# ESP32-C6 register map
Vendor: ESPRESSIF SYSTEMS (SHANGHAI) CO., LTD.; Series: ESP32 C-Series; File version: 12
CPU: RV32IMAC r0p0, little endian, no MPU, no FPU, 0 interrupt priority bits
Address unit: 32 bits
Registers are 32-bit, read-write, reset 0x0 unless marked. A register's access mark holds for its fields unless they carry their own. Offsets are from the block's base; [hi:lo] are bit positions.

## ASSIST_DEBUG — Debug Assist
Base 0x600C2000
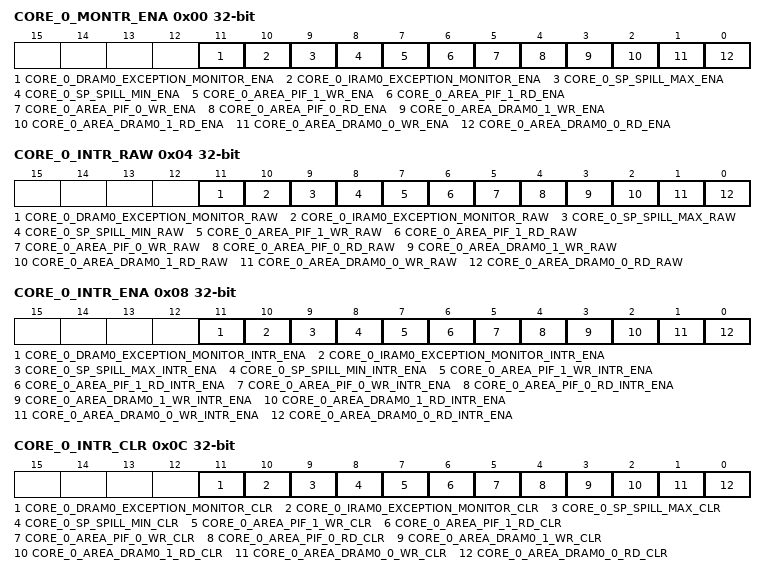
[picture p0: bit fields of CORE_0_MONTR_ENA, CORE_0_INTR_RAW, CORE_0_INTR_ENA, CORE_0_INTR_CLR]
0x00 CORE_0_MONTR_ENA — core0 monitor enable configuration register
  [11] CORE_0_DRAM0_EXCEPTION_MONITOR_ENA — DBUS busy monitor enbale
  [10] CORE_0_IRAM0_EXCEPTION_MONITOR_ENA — IBUS busy monitor enable
  [9] CORE_0_SP_SPILL_MAX_ENA — Core0 stackpoint overflow monitor enable
  [8] CORE_0_SP_SPILL_MIN_ENA — Core0 stackpoint underflow monitor enable
  [7] CORE_0_AREA_PIF_1_WR_ENA — Core0 PIF area1 write monitor enable
  [6] CORE_0_AREA_PIF_1_RD_ENA — Core0 PIF area1 read monitor enable
  [5] CORE_0_AREA_PIF_0_WR_ENA — Core0 PIF area0 write monitor enable
  [4] CORE_0_AREA_PIF_0_RD_ENA — Core0 PIF area0 read monitor enable
  [3] CORE_0_AREA_DRAM0_1_WR_ENA — Core0 dram0 area1 write monitor enable
  [2] CORE_0_AREA_DRAM0_1_RD_ENA — Core0 dram0 area1 read monitor enable
  [1] CORE_0_AREA_DRAM0_0_WR_ENA — Core0 dram0 area0 write monitor enable
  [0] CORE_0_AREA_DRAM0_0_RD_ENA — Core0 dram0 area0 read monitor enable
0x04 CORE_0_INTR_RAW ro — core0 monitor interrupt status register
  [11] CORE_0_DRAM0_EXCEPTION_MONITOR_RAW — DBUS busy monitor initerrupt status
  [10] CORE_0_IRAM0_EXCEPTION_MONITOR_RAW — IBUS busy monitor interrupt status
  [9] CORE_0_SP_SPILL_MAX_RAW — Core0 stackpoint overflow monitor interrupt status
  [8] CORE_0_SP_SPILL_MIN_RAW — Core0 stackpoint underflow monitor interrupt status
  [7] CORE_0_AREA_PIF_1_WR_RAW — Core0 PIF area1 write monitor interrupt status
  [6] CORE_0_AREA_PIF_1_RD_RAW — Core0 PIF area1 read monitor interrupt status
  [5] CORE_0_AREA_PIF_0_WR_RAW — Core0 PIF area0 write monitor interrupt status
  [4] CORE_0_AREA_PIF_0_RD_RAW — Core0 PIF area0 read monitor interrupt status
  [3] CORE_0_AREA_DRAM0_1_WR_RAW — Core0 dram0 area1 write monitor interrupt status
  [2] CORE_0_AREA_DRAM0_1_RD_RAW — Core0 dram0 area1 read monitor interrupt status
  [1] CORE_0_AREA_DRAM0_0_WR_RAW — Core0 dram0 area0 write monitor interrupt status
  [0] CORE_0_AREA_DRAM0_0_RD_RAW — Core0 dram0 area0 read monitor interrupt status
0x08 CORE_0_INTR_ENA — core0 monitor interrupt enable register
  [11] CORE_0_DRAM0_EXCEPTION_MONITOR_INTR_ENA — DBUS busy monitor interrupt enbale
  [10] CORE_0_IRAM0_EXCEPTION_MONITOR_INTR_ENA — IBUS busy monitor interrupt enable
  [9] CORE_0_SP_SPILL_MAX_INTR_ENA — Core0 stackpoint overflow monitor interrupt enable
  [8] CORE_0_SP_SPILL_MIN_INTR_ENA — Core0 stackpoint underflow monitor interrupt enable
  [7] CORE_0_AREA_PIF_1_WR_INTR_ENA — Core0 PIF area1 write monitor interrupt enable
  [6] CORE_0_AREA_PIF_1_RD_INTR_ENA — Core0 PIF area1 read monitor interrupt enable
  [5] CORE_0_AREA_PIF_0_WR_INTR_ENA — Core0 PIF area0 write monitor interrupt enable
  [4] CORE_0_AREA_PIF_0_RD_INTR_ENA — Core0 PIF area0 read monitor interrupt enable
  [3] CORE_0_AREA_DRAM0_1_WR_INTR_ENA — Core0 dram0 area1 write monitor interrupt enable
  [2] CORE_0_AREA_DRAM0_1_RD_INTR_ENA — Core0 dram0 area1 read monitor interrupt enable
  [1] CORE_0_AREA_DRAM0_0_WR_INTR_ENA — Core0 dram0 area0 write monitor interrupt enable
  [0] CORE_0_AREA_DRAM0_0_RD_INTR_ENA — Core0 dram0 area0 read monitor interrupt enable
0x0C CORE_0_INTR_CLR wo — core0 monitor interrupt clr register
  [11] CORE_0_DRAM0_EXCEPTION_MONITOR_CLR — DBUS busy monitor interrupt clr
  [10] CORE_0_IRAM0_EXCEPTION_MONITOR_CLR — IBUS busy monitor interrupt clr
  [9] CORE_0_SP_SPILL_MAX_CLR — Core0 stackpoint overflow monitor interrupt clr
  [8] CORE_0_SP_SPILL_MIN_CLR — Core0 stackpoint underflow monitor interrupt clr
  [7] CORE_0_AREA_PIF_1_WR_CLR — Core0 PIF area1 write monitor interrupt clr
  [6] CORE_0_AREA_PIF_1_RD_CLR — Core0 PIF area1 read monitor interrupt clr
  [5] CORE_0_AREA_PIF_0_WR_CLR — Core0 PIF area0 write monitor interrupt clr
  [4] CORE_0_AREA_PIF_0_RD_CLR — Core0 PIF area0 read monitor interrupt clr
  [3] CORE_0_AREA_DRAM0_1_WR_CLR — Core0 dram0 area1 write monitor interrupt clr
  [2] CORE_0_AREA_DRAM0_1_RD_CLR — Core0 dram0 area1 read monitor interrupt clr
  [1] CORE_0_AREA_DRAM0_0_WR_CLR — Core0 dram0 area0 write monitor interrupt clr
  [0] CORE_0_AREA_DRAM0_0_RD_CLR — Core0 dram0 area0 read monitor interrupt clr
0x10 CORE_0_AREA_DRAM0_0_MIN reset 0xFFFFFFFF — core0 dram0 region0 addr configuration register
  [31:0] CORE_0_AREA_DRAM0_0_MIN — Core0 dram0 region0 start addr
0x14 CORE_0_AREA_DRAM0_0_MAX — core0 dram0 region0 addr configuration register
  [31:0] CORE_0_AREA_DRAM0_0_MAX — Core0 dram0 region0 end addr
0x18 CORE_0_AREA_DRAM0_1_MIN reset 0xFFFFFFFF — core0 dram0 region1 addr configuration register
  [31:0] CORE_0_AREA_DRAM0_1_MIN — Core0 dram0 region1 start addr
0x1C CORE_0_AREA_DRAM0_1_MAX — core0 dram0 region1 addr configuration register
  [31:0] CORE_0_AREA_DRAM0_1_MAX — Core0 dram0 region1 end addr
0x20 CORE_0_AREA_PIF_0_MIN reset 0xFFFFFFFF — core0 PIF region0 addr configuration register
  [31:0] CORE_0_AREA_PIF_0_MIN — Core0 PIF region0 start addr
0x24 CORE_0_AREA_PIF_0_MAX — core0 PIF region0 addr configuration register
  [31:0] CORE_0_AREA_PIF_0_MAX — Core0 PIF region0 end addr
0x28 CORE_0_AREA_PIF_1_MIN reset 0xFFFFFFFF — core0 PIF region1 addr configuration register
  [31:0] CORE_0_AREA_PIF_1_MIN — Core0 PIF region1 start addr
0x2C CORE_0_AREA_PIF_1_MAX — core0 PIF region1 addr configuration register
  [31:0] CORE_0_AREA_PIF_1_MAX — Core0 PIF region1 end addr
0x30 CORE_0_AREA_PC ro — core0 area pc status register
  [31:0] CORE_0_AREA_PC — the stackpointer when first touch region monitor interrupt
0x34 CORE_0_AREA_SP ro — core0 area sp status register
  [31:0] CORE_0_AREA_SP — the PC when first touch region monitor interrupt
0x38 CORE_0_SP_MIN — stack min value
  [31:0] CORE_0_SP_MIN — core0 sp region configuration regsiter
0x3C CORE_0_SP_MAX reset 0xFFFFFFFF — stack max value
  [31:0] CORE_0_SP_MAX — core0 sp pc status register
0x40 CORE_0_SP_PC ro — stack monitor pc status register
  [31:0] CORE_0_SP_PC — This regsiter stores the PC when trigger stack monitor.
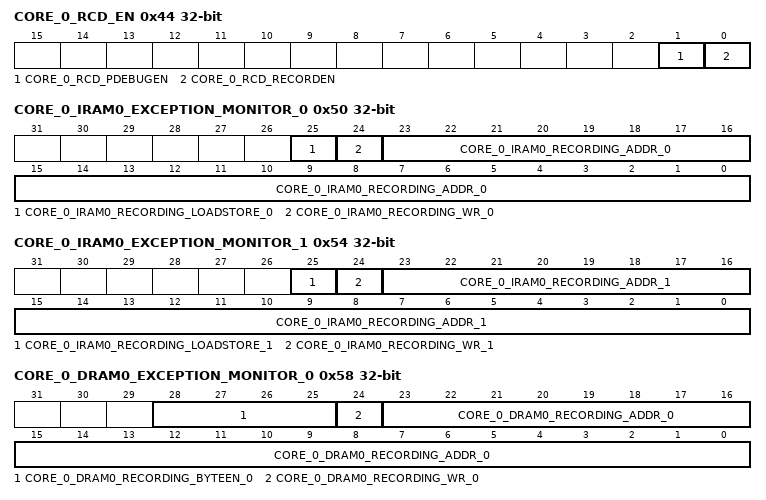
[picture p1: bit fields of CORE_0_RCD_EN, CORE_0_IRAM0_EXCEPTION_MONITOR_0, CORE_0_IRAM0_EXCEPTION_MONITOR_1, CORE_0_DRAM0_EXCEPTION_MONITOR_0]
0x44 CORE_0_RCD_EN — record enable configuration register
  [1] CORE_0_RCD_PDEBUGEN — Set 1 to enable cpu pdebug function, must set this bit can get cpu PC
  [0] CORE_0_RCD_RECORDEN — Set 1 to enable record PC
0x48 CORE_0_RCD_PDEBUGPC ro — record status regsiter
  [31:0] CORE_0_RCD_PDEBUGPC — recorded PC
0x4C CORE_0_RCD_PDEBUGSP ro — record status regsiter
  [31:0] CORE_0_RCD_PDEBUGSP — recorded sp
0x50 CORE_0_IRAM0_EXCEPTION_MONITOR_0 ro — exception monitor status register0
  [25] CORE_0_IRAM0_RECORDING_LOADSTORE_0 — reg_core_0_iram0_recording_loadstore_0
  [24] CORE_0_IRAM0_RECORDING_WR_0 — reg_core_0_iram0_recording_wr_0
  [23:0] CORE_0_IRAM0_RECORDING_ADDR_0 — reg_core_0_iram0_recording_addr_0
0x54 CORE_0_IRAM0_EXCEPTION_MONITOR_1 ro — exception monitor status register1
  [25] CORE_0_IRAM0_RECORDING_LOADSTORE_1 — reg_core_0_iram0_recording_loadstore_1
  [24] CORE_0_IRAM0_RECORDING_WR_1 — reg_core_0_iram0_recording_wr_1
  [23:0] CORE_0_IRAM0_RECORDING_ADDR_1 — reg_core_0_iram0_recording_addr_1
0x58 CORE_0_DRAM0_EXCEPTION_MONITOR_0 ro — exception monitor status register2
  [28:25] CORE_0_DRAM0_RECORDING_BYTEEN_0 — reg_core_0_dram0_recording_byteen_0
  [24] CORE_0_DRAM0_RECORDING_WR_0 — reg_core_0_dram0_recording_wr_0
  [23:0] CORE_0_DRAM0_RECORDING_ADDR_0 — reg_core_0_dram0_recording_addr_0
0x5C CORE_0_DRAM0_EXCEPTION_MONITOR_1 ro — exception monitor status register3
  [31:0] CORE_0_DRAM0_RECORDING_PC_0 — reg_core_0_dram0_recording_pc_0
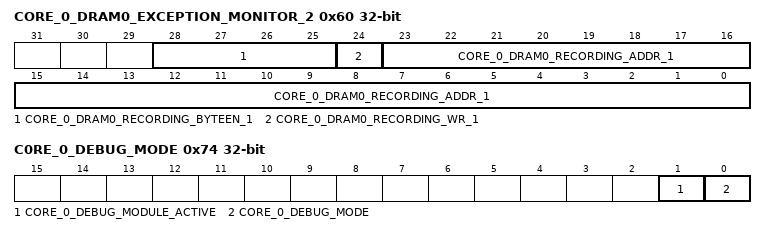
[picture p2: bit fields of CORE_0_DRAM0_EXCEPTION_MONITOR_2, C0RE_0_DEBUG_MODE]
0x60 CORE_0_DRAM0_EXCEPTION_MONITOR_2 ro — exception monitor status register4
  [28:25] CORE_0_DRAM0_RECORDING_BYTEEN_1 — reg_core_0_dram0_recording_byteen_1
  [24] CORE_0_DRAM0_RECORDING_WR_1 — reg_core_0_dram0_recording_wr_1
  [23:0] CORE_0_DRAM0_RECORDING_ADDR_1 — reg_core_0_dram0_recording_addr_1
0x64 CORE_0_DRAM0_EXCEPTION_MONITOR_3 ro — exception monitor status register5
  [31:0] CORE_0_DRAM0_RECORDING_PC_1 — reg_core_0_dram0_recording_pc_1
0x68 CORE_X_IRAM0_DRAM0_EXCEPTION_MONITOR_0 — exception monitor status register6
  [19:0] CORE_X_IRAM0_DRAM0_LIMIT_CYCLE_0 — reg_core_x_iram0_dram0_limit_cycle_0
0x6C CORE_X_IRAM0_DRAM0_EXCEPTION_MONITOR_1 — exception monitor status register7
  [19:0] CORE_X_IRAM0_DRAM0_LIMIT_CYCLE_1 — reg_core_x_iram0_dram0_limit_cycle_1
0x70 C0RE_0_LASTPC_BEFORE_EXCEPTION ro — cpu status register
  [31:0] CORE_0_LASTPC_BEFORE_EXC — cpu's lastpc before exception
0x74 C0RE_0_DEBUG_MODE ro — cpu status register
  [1] CORE_0_DEBUG_MODULE_ACTIVE — cpu debug_module active status
  [0] CORE_0_DEBUG_MODE — cpu debug mode status, 1 means cpu enter debug mode.
0x78 CLOCK_GATE reset 0x1 — clock register
  [0] CLK_EN — Set 1 force on the clock gate
0x3FC DATE reset 0x2109130 — version register
  [27:0] ASSIST_DEBUG_DATE

## Notices in the file
Copyright 2025 Espressif Systems (Shanghai) PTE LTD
Licensed under the Apache License, Version 2.0 (the "License");
you may not use this file except in compliance with the License.
You may obtain a copy of the License at
http://www.apache.org/licenses/LICENSE-2.0
Unless required by applicable law or agreed to in writing, software
distributed under the License is distributed on an "AS IS" BASIS,
WITHOUT WARRANTIES OR CONDITIONS OF ANY KIND, either express or implied.
See the License for the specific language governing permissions and
limitations under the License.
